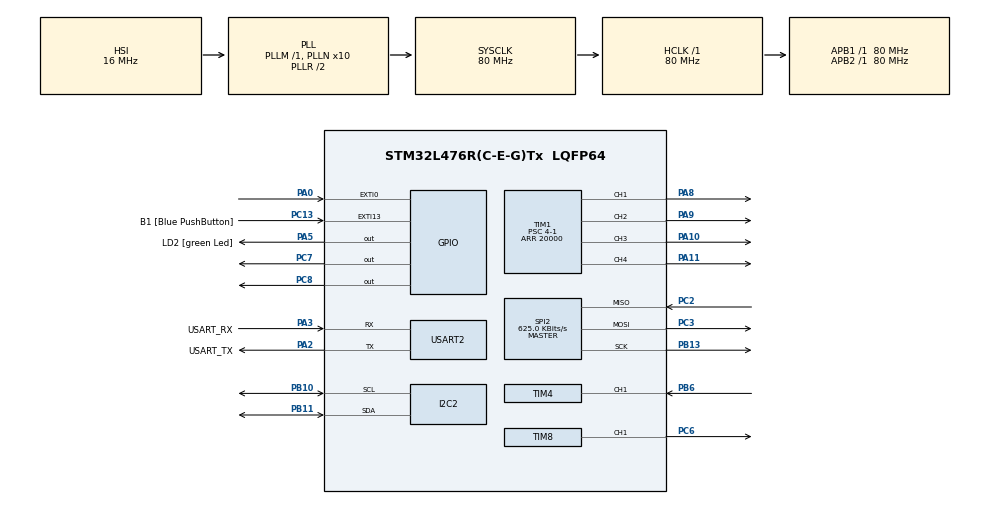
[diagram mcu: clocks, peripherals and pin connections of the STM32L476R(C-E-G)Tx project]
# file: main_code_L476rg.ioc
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I2C2.Timing=0x10D19CE4
Mcu.Family=STM32L4
Mcu.Name=STM32L476R(C-E-G)Tx
Mcu.Package=LQFP64
NVIC.EXTI0_IRQn=true\:0\:0\:false\:false\:true\:true\:true\:true
NVIC.PriorityGroup=NVIC_PRIORITYGROUP_4
NVIC.TIM2_IRQn=true\:0\:0\:false\:false\:true\:true\:true\:true
NVIC.TIM3_IRQn=true\:0\:0\:false\:false\:true\:true\:true\:true
NVIC.TIM4_IRQn=true\:0\:0\:false\:false\:true\:true\:true\:true
NVIC.USART2_IRQn=true\:0\:0\:false\:false\:true\:true\:true\:true
PA0.GPIO_ModeDefaultEXTI=GPIO_MODE_IT_FALLING
PA0.Signal=GPXTI0
PA10.Signal=S_TIM1_CH3
PA11.Signal=S_TIM1_CH4
PA13\ (JTMS-SWDIO).GPIO_Label=TMS
PA13\ (JTMS-SWDIO).Mode=Serial_Wire
PA13\ (JTMS-SWDIO).Signal=SYS_JTMS-SWDIO
PA14\ (JTCK-SWCLK).GPIO_Label=TCK
PA14\ (JTCK-SWCLK).Mode=Serial_Wire
PA14\ (JTCK-SWCLK).Signal=SYS_JTCK-SWCLK
PA2.GPIO_Label=USART_TX
PA2.GPIO_Mode=GPIO_MODE_AF_PP
PA2.GPIO_PuPd=GPIO_NOPULL
PA2.GPIO_Speed=GPIO_SPEED_FREQ_VERY_HIGH
PA2.Mode=Asynchronous
PA2.Signal=USART2_TX
PA3.GPIO_Label=USART_RX
PA3.GPIO_Mode=GPIO_MODE_AF_PP
PA3.GPIO_PuPd=GPIO_NOPULL
PA3.GPIO_Speed=GPIO_SPEED_FREQ_VERY_HIGH
PA3.Mode=Asynchronous
PA3.Signal=USART2_RX
PA5.GPIO_Label=LD2 [green Led]
PA5.GPIO_ModeDefaultOutputPP=GPIO_MODE_OUTPUT_PP
PA5.GPIO_PuPd=GPIO_NOPULL
PA5.GPIO_Speed=GPIO_SPEED_FREQ_LOW
PA5.Signal=GPIO_Output
PA8.Signal=S_TIM1_CH1
PA9.Signal=S_TIM1_CH2
PB10.Mode=I2C
PB10.Signal=I2C2_SCL
PB11.Mode=I2C
PB11.Signal=I2C2_SDA
PB13.Mode=Full_Duplex_Master
PB13.Signal=SPI2_SCK
PB3\ (JTDO-TRACESWO).GPIO_Label=SWO
PB3\ (JTDO-TRACESWO).Signal=SYS_JTDO-SWO
PB6.Signal=S_TIM4_CH1
PC13.GPIO_Label=B1 [Blue PushButton]
PC13.GPIO_ModeDefaultEXTI=GPIO_MODE_IT_FALLING
PC13.GPIO_PuPd=GPIO_NOPULL
PC13.Signal=GPXTI13
PC14-OSC32_IN\ (PC14).Mode=LSE-External-Oscillator
PC14-OSC32_IN\ (PC14).Signal=RCC_OSC32_IN
PC15-OSC32_OUT\ (PC15).Mode=LSE-External-Oscillator
PC15-OSC32_OUT\ (PC15).Signal=RCC_OSC32_OUT
PC2.Mode=Full_Duplex_Master
PC2.Signal=SPI2_MISO
PC3.Mode=Full_Duplex_Master
PC3.Signal=SPI2_MOSI
PC6.Signal=S_TIM8_CH1
PC7.PinState=GPIO_PIN_SET
PC7.Signal=GPIO_Output
PC8.Signal=GPIO_Output
PH0-OSC_IN\ (PH0).Signal=RCC_OSC_IN
PH1-OSC_OUT\ (PH1).Signal=RCC_OSC_OUT
ProjectManager.HeapSize=0x200
ProjectManager.StackSize=0x400
ProjectManager.TargetToolchain=STM32CubeIDE
RCC.ADCFreq_Value=64000000
RCC.AHBFreq_Value=80000000
RCC.APB1Freq_Value=80000000
RCC.APB1TimFreq_Value=80000000
RCC.APB2Freq_Value=80000000
RCC.APB2TimFreq_Value=80000000
RCC.CortexFreq_Value=80000000
RCC.HCLKFreq_Value=80000000
RCC.HSE_VALUE=8000000
RCC.HSI_VALUE=16000000
RCC.MSI_VALUE=4000000
RCC.PLLN=10
RCC.PLLSourceVirtual=RCC_PLLSOURCE_HSI
RCC.PREFETCH_ENABLE=1
RCC.SYSCLKFreq_VALUE=80000000
RCC.SYSCLKSource=RCC_SYSCLKSOURCE_PLLCLK
RCC.USBFreq_Value=64000000
RCC.VCOOutputFreq_Value=160000000
SH.S_TIM1_CH1.0=TIM1_CH1,PWM Generation1 CH1
SH.S_TIM1_CH2.0=TIM1_CH2,PWM Generation2 CH2
SH.S_TIM1_CH3.0=TIM1_CH3,PWM Generation3 CH3
SH.S_TIM1_CH4.0=TIM1_CH4,PWM Generation4 CH4
SH.S_TIM4_CH1.0=TIM4_CH1,Input_Capture1_from_TI1
SH.S_TIM8_CH1.0=TIM8_CH1,PWM Generation1 CH1
SPI2.BaudRatePrescaler=SPI_BAUDRATEPRESCALER_128
SPI2.CalculateBaudRate=625.0 KBits/s
SPI2.DataSize=SPI_DATASIZE_8BIT
SPI2.Direction=SPI_DIRECTION_2LINES
SPI2.Mode=SPI_MODE_MASTER
SPI2.VirtualType=VM_MASTER
TIM1.Channel-PWM\ Generation1\ CH1=TIM_CHANNEL_1
TIM1.Channel-PWM\ Generation2\ CH2=TIM_CHANNEL_2
TIM1.Channel-PWM\ Generation3\ CH3=TIM_CHANNEL_3
TIM1.Channel-PWM\ Generation4\ CH4=TIM_CHANNEL_4
TIM1.Period=20000
TIM1.Prescaler=4-1
TIM2.Period=200
TIM2.Prescaler=8000-1
TIM4.Channel-Input_Capture1_from_TI1=TIM_CHANNEL_1
TIM4.ICPolarity_CH1=TIM_INPUTCHANNELPOLARITY_BOTHEDGE
TIM4.Prescaler=80-1
TIM5.Prescaler=80-1
TIM8.Channel-PWM\ Generation1\ CH1=TIM_CHANNEL_1
TIM8.Period=65535
TIM8.Prescaler=80-1
TIM8.Pulse-PWM\ Generation1\ CH1=250
USART2.VirtualMode-Asynchronous=VM_ASYNC
VP_TIM1_VS_ClockSourceINT.Mode=Internal
VP_TIM2_VS_ClockSourceINT.Mode=Internal
VP_TIM3_VS_ClockSourceINT.Mode=Internal
VP_TIM4_VS_ClockSourceINT.Mode=Internal
VP_TIM5_VS_ClockSourceINT.Mode=Internal
VP_TIM8_VS_ClockSourceINT.Mode=Internal
board=NUCLEO-L476RG

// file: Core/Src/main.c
/* USER CODE BEGIN Header */
/**
  ******************************************************************************
  * @file           : main.c
  * @brief          : Main program body
  ******************************************************************************
  * @attention
  *
  * Copyright (c) 2025 STMicroelectronics.
  * All rights reserved.
  *
  * This software is licensed under terms that can be found in the LICENSE file
  * in the root directory of this software component.
  * If no LICENSE file comes with this software, it is provided AS-IS.
  *
  ******************************************************************************
  */
/* USER CODE END Header */
#include "main.h"

/* USER CODE BEGIN Includes */
#include "mainloop.h"
#include "nrf24l01p.h"
/* USER CODE END Includes */

I2C_HandleTypeDef hi2c2;

SPI_HandleTypeDef hspi2;

TIM_HandleTypeDef htim1;
TIM_HandleTypeDef htim2;
TIM_HandleTypeDef htim3;
TIM_HandleTypeDef htim4;
TIM_HandleTypeDef htim5;
TIM_HandleTypeDef htim8;

UART_HandleTypeDef huart2;

/* USER CODE BEGIN PV */
uint8_t rx_data[NRF24L01P_PAYLOAD_LENGTH] = {0};
uint8_t receivedString[NRF24L01P_PAYLOAD_LENGTH] = {0};
int flag = 0;
/* USER CODE END PV */

void SystemClock_Config(void);
static void MX_GPIO_Init(void);
static void MX_USART2_UART_Init(void);
static void MX_TIM1_Init(void);
static void MX_TIM2_Init(void);
static void MX_TIM3_Init(void);
static void MX_TIM4_Init(void);
static void MX_TIM5_Init(void);
static void MX_I2C2_Init(void);
static void MX_TIM8_Init(void);
static void MX_SPI2_Init(void);

/* USER CODE BEGIN 0 */

void HAL_GPIO_EXTI_Callback(uint16_t GPIO_Pin) {

	if(GPIO_Pin == NRF24L01P_IRQ_PIN_NUMBER) {
		HAL_GPIO_TogglePin(GPIOA, GPIO_PIN_5);
	    nrf24l01p_rx_receive(rx_data);
	    command_handler(rx_data);
	    flag = 1;
	}

}

/* USER CODE END 0 */

int main(void)
{

  /* MCU Configuration--------------------------------------------------------*/

  /* Reset of all peripherals, Initializes the Flash interface and the Systick. */
  HAL_Init();

  /* Configure the system clock */
  SystemClock_Config();

  /* Initialize all configured peripherals */
  MX_GPIO_Init();
  MX_USART2_UART_Init();
  MX_TIM1_Init();
  MX_TIM2_Init();
  MX_TIM3_Init();
  MX_TIM4_Init();
  MX_TIM5_Init();
  MX_I2C2_Init();
  MX_TIM8_Init();
  MX_SPI2_Init();
  /* USER CODE BEGIN 2 */
//  nrf24l01p_rx_init(2500, _250kbps);
  run();
  /* USER CODE END 2 */

  /* Infinite loop */
  while (1)
  {

  }
}

void SystemClock_Config(void)
{
  RCC_OscInitTypeDef RCC_OscInitStruct = {0};
  RCC_ClkInitTypeDef RCC_ClkInitStruct = {0};

  /** Configure the main internal regulator output voltage
  */
  if (HAL_PWREx_ControlVoltageScaling(PWR_REGULATOR_VOLTAGE_SCALE1) != HAL_OK)
  {
    Error_Handler();
  }

  /** Initializes the RCC Oscillators according to the specified parameters
  * in the RCC_OscInitTypeDef structure.
  */
  RCC_OscInitStruct.OscillatorType = RCC_OSCILLATORTYPE_HSI;
  RCC_OscInitStruct.HSIState = RCC_HSI_ON;
  RCC_OscInitStruct.HSICalibrationValue = RCC_HSICALIBRATION_DEFAULT;
  RCC_OscInitStruct.PLL.PLLState = RCC_PLL_ON;
  RCC_OscInitStruct.PLL.PLLSource = RCC_PLLSOURCE_HSI;
  RCC_OscInitStruct.PLL.PLLM = 1;
  RCC_OscInitStruct.PLL.PLLN = 10;
  RCC_OscInitStruct.PLL.PLLP = RCC_PLLP_DIV7;
  RCC_OscInitStruct.PLL.PLLQ = RCC_PLLQ_DIV2;
  RCC_OscInitStruct.PLL.PLLR = RCC_PLLR_DIV2;
  if (HAL_RCC_OscConfig(&RCC_OscInitStruct) != HAL_OK)
  {
    Error_Handler();
  }

  /** Initializes the CPU, AHB and APB buses clocks
  */
  RCC_ClkInitStruct.ClockType = RCC_CLOCKTYPE_HCLK|RCC_CLOCKTYPE_SYSCLK
                              |RCC_CLOCKTYPE_PCLK1|RCC_CLOCKTYPE_PCLK2;
  RCC_ClkInitStruct.SYSCLKSource = RCC_SYSCLKSOURCE_PLLCLK;
  RCC_ClkInitStruct.AHBCLKDivider = RCC_SYSCLK_DIV1;
  RCC_ClkInitStruct.APB1CLKDivider = RCC_HCLK_DIV1;
  RCC_ClkInitStruct.APB2CLKDivider = RCC_HCLK_DIV1;

  if (HAL_RCC_ClockConfig(&RCC_ClkInitStruct, FLASH_LATENCY_4) != HAL_OK)
  {
    Error_Handler();
  }
}

static void MX_I2C2_Init(void)
{

  hi2c2.Instance = I2C2;
  hi2c2.Init.Timing = 0x10D19CE4;
  hi2c2.Init.OwnAddress1 = 0;
  hi2c2.Init.AddressingMode = I2C_ADDRESSINGMODE_7BIT;
  hi2c2.Init.DualAddressMode = I2C_DUALADDRESS_DISABLE;
  hi2c2.Init.OwnAddress2 = 0;
  hi2c2.Init.OwnAddress2Masks = I2C_OA2_NOMASK;
  hi2c2.Init.GeneralCallMode = I2C_GENERALCALL_DISABLE;
  hi2c2.Init.NoStretchMode = I2C_NOSTRETCH_DISABLE;
  if (HAL_I2C_Init(&hi2c2) != HAL_OK)
  {
    Error_Handler();
  }

  /** Configure Analogue filter
  */
  if (HAL_I2CEx_ConfigAnalogFilter(&hi2c2, I2C_ANALOGFILTER_ENABLE) != HAL_OK)
  {
    Error_Handler();
  }

  /** Configure Digital filter
  */
  if (HAL_I2CEx_ConfigDigitalFilter(&hi2c2, 0) != HAL_OK)
  {
    Error_Handler();
  }

}

static void MX_SPI2_Init(void)
{

  /* SPI2 parameter configuration*/
  hspi2.Instance = SPI2;
  hspi2.Init.Mode = SPI_MODE_MASTER;
  hspi2.Init.Direction = SPI_DIRECTION_2LINES;
  hspi2.Init.DataSize = SPI_DATASIZE_8BIT;
  hspi2.Init.CLKPolarity = SPI_POLARITY_LOW;
  hspi2.Init.CLKPhase = SPI_PHASE_1EDGE;
  hspi2.Init.NSS = SPI_NSS_SOFT;
  hspi2.Init.BaudRatePrescaler = SPI_BAUDRATEPRESCALER_128;
  hspi2.Init.FirstBit = SPI_FIRSTBIT_MSB;
  hspi2.Init.TIMode = SPI_TIMODE_DISABLE;
  hspi2.Init.CRCCalculation = SPI_CRCCALCULATION_DISABLE;
  hspi2.Init.CRCPolynomial = 7;
  hspi2.Init.CRCLength = SPI_CRC_LENGTH_DATASIZE;
  hspi2.Init.NSSPMode = SPI_NSS_PULSE_ENABLE;
  if (HAL_SPI_Init(&hspi2) != HAL_OK)
  {
    Error_Handler();
  }

}

static void MX_TIM1_Init(void)
{

  TIM_ClockConfigTypeDef sClockSourceConfig = {0};
  TIM_MasterConfigTypeDef sMasterConfig = {0};
  TIM_OC_InitTypeDef sConfigOC = {0};
  TIM_BreakDeadTimeConfigTypeDef sBreakDeadTimeConfig = {0};

  htim1.Instance = TIM1;
  htim1.Init.Prescaler = 4-1;
  htim1.Init.CounterMode = TIM_COUNTERMODE_UP;
  htim1.Init.Period = 20000;
  htim1.Init.ClockDivision = TIM_CLOCKDIVISION_DIV1;
  htim1.Init.RepetitionCounter = 0;
  htim1.Init.AutoReloadPreload = TIM_AUTORELOAD_PRELOAD_DISABLE;
  if (HAL_TIM_Base_Init(&htim1) != HAL_OK)
  {
    Error_Handler();
  }
  sClockSourceConfig.ClockSource = TIM_CLOCKSOURCE_INTERNAL;
  if (HAL_TIM_ConfigClockSource(&htim1, &sClockSourceConfig) != HAL_OK)
  {
    Error_Handler();
  }
  if (HAL_TIM_PWM_Init(&htim1) != HAL_OK)
  {
    Error_Handler();
  }
  sMasterConfig.MasterOutputTrigger = TIM_TRGO_RESET;
  sMasterConfig.MasterOutputTrigger2 = TIM_TRGO2_RESET;
  sMasterConfig.MasterSlaveMode = TIM_MASTERSLAVEMODE_DISABLE;
  if (HAL_TIMEx_MasterConfigSynchronization(&htim1, &sMasterConfig) != HAL_OK)
  {
    Error_Handler();
  }
  sConfigOC.OCMode = TIM_OCMODE_PWM1;
  sConfigOC.Pulse = 0;
  sConfigOC.OCPolarity = TIM_OCPOLARITY_HIGH;
  sConfigOC.OCNPolarity = TIM_OCNPOLARITY_HIGH;
  sConfigOC.OCFastMode = TIM_OCFAST_DISABLE;
  sConfigOC.OCIdleState = TIM_OCIDLESTATE_RESET;
  sConfigOC.OCNIdleState = TIM_OCNIDLESTATE_RESET;
  if (HAL_TIM_PWM_ConfigChannel(&htim1, &sConfigOC, TIM_CHANNEL_1) != HAL_OK)
  {
    Error_Handler();
  }
  if (HAL_TIM_PWM_ConfigChannel(&htim1, &sConfigOC, TIM_CHANNEL_2) != HAL_OK)
  {
    Error_Handler();
  }
  if (HAL_TIM_PWM_ConfigChannel(&htim1, &sConfigOC, TIM_CHANNEL_3) != HAL_OK)
  {
    Error_Handler();
  }
  if (HAL_TIM_PWM_ConfigChannel(&htim1, &sConfigOC, TIM_CHANNEL_4) != HAL_OK)
  {
    Error_Handler();
  }
  sBreakDeadTimeConfig.OffStateRunMode = TIM_OSSR_DISABLE;
  sBreakDeadTimeConfig.OffStateIDLEMode = TIM_OSSI_DISABLE;
  sBreakDeadTimeConfig.LockLevel = TIM_LOCKLEVEL_OFF;
  sBreakDeadTimeConfig.DeadTime = 0;
  sBreakDeadTimeConfig.BreakState = TIM_BREAK_DISABLE;
  sBreakDeadTimeConfig.BreakPolarity = TIM_BREAKPOLARITY_HIGH;
  sBreakDeadTimeConfig.BreakFilter = 0;
  sBreakDeadTimeConfig.Break2State = TIM_BREAK2_DISABLE;
  sBreakDeadTimeConfig.Break2Polarity = TIM_BREAK2POLARITY_HIGH;
  sBreakDeadTimeConfig.Break2Filter = 0;
  sBreakDeadTimeConfig.AutomaticOutput = TIM_AUTOMATICOUTPUT_DISABLE;
  if (HAL_TIMEx_ConfigBreakDeadTime(&htim1, &sBreakDeadTimeConfig) != HAL_OK)
  {
    Error_Handler();
  }
  HAL_TIM_MspPostInit(&htim1);

}

static void MX_TIM2_Init(void)
{

  TIM_ClockConfigTypeDef sClockSourceConfig = {0};
  TIM_MasterConfigTypeDef sMasterConfig = {0};

  htim2.Instance = TIM2;
  htim2.Init.Prescaler = 8000-1;
  htim2.Init.CounterMode = TIM_COUNTERMODE_UP;
  htim2.Init.Period = 200;
  htim2.Init.ClockDivision = TIM_CLOCKDIVISION_DIV1;
  htim2.Init.AutoReloadPreload = TIM_AUTORELOAD_PRELOAD_DISABLE;
  if (HAL_TIM_Base_Init(&htim2) != HAL_OK)
  {
    Error_Handler();
  }
  sClockSourceConfig.ClockSource = TIM_CLOCKSOURCE_INTERNAL;
  if (HAL_TIM_ConfigClockSource(&htim2, &sClockSourceConfig) != HAL_OK)
  {
    Error_Handler();
  }
  sMasterConfig.MasterOutputTrigger = TIM_TRGO_RESET;
  sMasterConfig.MasterSlaveMode = TIM_MASTERSLAVEMODE_DISABLE;
  if (HAL_TIMEx_MasterConfigSynchronization(&htim2, &sMasterConfig) != HAL_OK)
  {
    Error_Handler();
  }

}

static void MX_TIM3_Init(void)
{

  TIM_ClockConfigTypeDef sClockSourceConfig = {0};
  TIM_MasterConfigTypeDef sMasterConfig = {0};

  htim3.Instance = TIM3;
  htim3.Init.Prescaler = 0;
  htim3.Init.CounterMode = TIM_COUNTERMODE_UP;
  htim3.Init.Period = 65535;
  htim3.Init.ClockDivision = TIM_CLOCKDIVISION_DIV1;
  htim3.Init.AutoReloadPreload = TIM_AUTORELOAD_PRELOAD_DISABLE;
  if (HAL_TIM_Base_Init(&htim3) != HAL_OK)
  {
    Error_Handler();
  }
  sClockSourceConfig.ClockSource = TIM_CLOCKSOURCE_INTERNAL;
  if (HAL_TIM_ConfigClockSource(&htim3, &sClockSourceConfig) != HAL_OK)
  {
    Error_Handler();
  }
  sMasterConfig.MasterOutputTrigger = TIM_TRGO_RESET;
  sMasterConfig.MasterSlaveMode = TIM_MASTERSLAVEMODE_DISABLE;
  if (HAL_TIMEx_MasterConfigSynchronization(&htim3, &sMasterConfig) != HAL_OK)
  {
    Error_Handler();
  }

}

static void MX_TIM4_Init(void)
{

  TIM_ClockConfigTypeDef sClockSourceConfig = {0};
  TIM_MasterConfigTypeDef sMasterConfig = {0};
  TIM_IC_InitTypeDef sConfigIC = {0};

  htim4.Instance = TIM4;
  htim4.Init.Prescaler = 80-1;
  htim4.Init.CounterMode = TIM_COUNTERMODE_UP;
  htim4.Init.Period = 65535;
  htim4.Init.ClockDivision = TIM_CLOCKDIVISION_DIV1;
  htim4.Init.AutoReloadPreload = TIM_AUTORELOAD_PRELOAD_DISABLE;
  if (HAL_TIM_Base_Init(&htim4) != HAL_OK)
  {
    Error_Handler();
  }
  sClockSourceConfig.ClockSource = TIM_CLOCKSOURCE_INTERNAL;
  if (HAL_TIM_ConfigClockSource(&htim4, &sClockSourceConfig) != HAL_OK)
  {
    Error_Handler();
  }
  if (HAL_TIM_IC_Init(&htim4) != HAL_OK)
  {
    Error_Handler();
  }
  sMasterConfig.MasterOutputTrigger = TIM_TRGO_RESET;
  sMasterConfig.MasterSlaveMode = TIM_MASTERSLAVEMODE_DISABLE;
  if (HAL_TIMEx_MasterConfigSynchronization(&htim4, &sMasterConfig) != HAL_OK)
  {
    Error_Handler();
  }
  sConfigIC.ICPolarity = TIM_INPUTCHANNELPOLARITY_BOTHEDGE;
  sConfigIC.ICSelection = TIM_ICSELECTION_DIRECTTI;
  sConfigIC.ICPrescaler = TIM_ICPSC_DIV1;
  sConfigIC.ICFilter = 0;
  if (HAL_TIM_IC_ConfigChannel(&htim4, &sConfigIC, TIM_CHANNEL_1) != HAL_OK)
  {
    Error_Handler();
  }

}

static void MX_TIM5_Init(void)
{

  TIM_ClockConfigTypeDef sClockSourceConfig = {0};
  TIM_MasterConfigTypeDef sMasterConfig = {0};

  htim5.Instance = TIM5;
  htim5.Init.Prescaler = 80-1;
  htim5.Init.CounterMode = TIM_COUNTERMODE_UP;
  htim5.Init.Period = 4294967295;
  htim5.Init.ClockDivision = TIM_CLOCKDIVISION_DIV1;
  htim5.Init.AutoReloadPreload = TIM_AUTORELOAD_PRELOAD_DISABLE;
  if (HAL_TIM_Base_Init(&htim5) != HAL_OK)
  {
    Error_Handler();
  }
  sClockSourceConfig.ClockSource = TIM_CLOCKSOURCE_INTERNAL;
  if (HAL_TIM_ConfigClockSource(&htim5, &sClockSourceConfig) != HAL_OK)
  {
    Error_Handler();
  }
  sMasterConfig.MasterOutputTrigger = TIM_TRGO_RESET;
  sMasterConfig.MasterSlaveMode = TIM_MASTERSLAVEMODE_DISABLE;
  if (HAL_TIMEx_MasterConfigSynchronization(&htim5, &sMasterConfig) != HAL_OK)
  {
    Error_Handler();
  }

}

static void MX_TIM8_Init(void)
{

  TIM_ClockConfigTypeDef sClockSourceConfig = {0};
  TIM_MasterConfigTypeDef sMasterConfig = {0};
  TIM_OC_InitTypeDef sConfigOC = {0};
  TIM_BreakDeadTimeConfigTypeDef sBreakDeadTimeConfig = {0};

  htim8.Instance = TIM8;
  htim8.Init.Prescaler = 80-1;
  htim8.Init.CounterMode = TIM_COUNTERMODE_UP;
  htim8.Init.Period = 65535;
  htim8.Init.ClockDivision = TIM_CLOCKDIVISION_DIV1;
  htim8.Init.RepetitionCounter = 0;
  htim8.Init.AutoReloadPreload = TIM_AUTORELOAD_PRELOAD_DISABLE;
  if (HAL_TIM_Base_Init(&htim8) != HAL_OK)
  {
    Error_Handler();
  }
  sClockSourceConfig.ClockSource = TIM_CLOCKSOURCE_INTERNAL;
  if (HAL_TIM_ConfigClockSource(&htim8, &sClockSourceConfig) != HAL_OK)
  {
    Error_Handler();
  }
  if (HAL_TIM_PWM_Init(&htim8) != HAL_OK)
  {
    Error_Handler();
  }
  sMasterConfig.MasterOutputTrigger = TIM_TRGO_RESET;
  sMasterConfig.MasterOutputTrigger2 = TIM_TRGO2_RESET;
  sMasterConfig.MasterSlaveMode = TIM_MASTERSLAVEMODE_DISABLE;
  if (HAL_TIMEx_MasterConfigSynchronization(&htim8, &sMasterConfig) != HAL_OK)
  {
    Error_Handler();
  }
  sConfigOC.OCMode = TIM_OCMODE_PWM1;
  sConfigOC.Pulse = 250;
  sConfigOC.OCPolarity = TIM_OCPOLARITY_HIGH;
  sConfigOC.OCNPolarity = TIM_OCNPOLARITY_HIGH;
  sConfigOC.OCFastMode = TIM_OCFAST_DISABLE;
  sConfigOC.OCIdleState = TIM_OCIDLESTATE_RESET;
  sConfigOC.OCNIdleState = TIM_OCNIDLESTATE_RESET;
  if (HAL_TIM_PWM_ConfigChannel(&htim8, &sConfigOC, TIM_CHANNEL_1) != HAL_OK)
  {
    Error_Handler();
  }
  sBreakDeadTimeConfig.OffStateRunMode = TIM_OSSR_DISABLE;
  sBreakDeadTimeConfig.OffStateIDLEMode = TIM_OSSI_DISABLE;
  sBreakDeadTimeConfig.LockLevel = TIM_LOCKLEVEL_OFF;
  sBreakDeadTimeConfig.DeadTime = 0;
  sBreakDeadTimeConfig.BreakState = TIM_BREAK_DISABLE;
  sBreakDeadTimeConfig.BreakPolarity = TIM_BREAKPOLARITY_HIGH;
  sBreakDeadTimeConfig.BreakFilter = 0;
  sBreakDeadTimeConfig.Break2State = TIM_BREAK2_DISABLE;
  sBreakDeadTimeConfig.Break2Polarity = TIM_BREAK2POLARITY_HIGH;
  sBreakDeadTimeConfig.Break2Filter = 0;
  sBreakDeadTimeConfig.AutomaticOutput = TIM_AUTOMATICOUTPUT_DISABLE;
  if (HAL_TIMEx_ConfigBreakDeadTime(&htim8, &sBreakDeadTimeConfig) != HAL_OK)
  {
    Error_Handler();
  }
  HAL_TIM_MspPostInit(&htim8);

}

static void MX_USART2_UART_Init(void)
{

  huart2.Instance = USART2;
  huart2.Init.BaudRate = 115200;
  huart2.Init.WordLength = UART_WORDLENGTH_8B;
  huart2.Init.StopBits = UART_STOPBITS_1;
  huart2.Init.Parity = UART_PARITY_NONE;
  huart2.Init.Mode = UART_MODE_TX_RX;
  huart2.Init.HwFlowCtl = UART_HWCONTROL_NONE;
  huart2.Init.OverSampling = UART_OVERSAMPLING_16;
  huart2.Init.OneBitSampling = UART_ONE_BIT_SAMPLE_DISABLE;
  huart2.AdvancedInit.AdvFeatureInit = UART_ADVFEATURE_NO_INIT;
  if (HAL_UART_Init(&huart2) != HAL_OK)
  {
    Error_Handler();
  }

}

static void MX_GPIO_Init(void)
{
  GPIO_InitTypeDef GPIO_InitStruct = {0};

  /* GPIO Ports Clock Enable */
  __HAL_RCC_GPIOC_CLK_ENABLE();
  __HAL_RCC_GPIOH_CLK_ENABLE();
  __HAL_RCC_GPIOA_CLK_ENABLE();
  __HAL_RCC_GPIOB_CLK_ENABLE();

  /*Configure GPIO pin Output Level */
  HAL_GPIO_WritePin(LD2_GPIO_Port, LD2_Pin, GPIO_PIN_RESET);

  /*Configure GPIO pin Output Level */
  HAL_GPIO_WritePin(GPIOC, GPIO_PIN_7, GPIO_PIN_SET);

  /*Configure GPIO pin Output Level */
  HAL_GPIO_WritePin(GPIOC, GPIO_PIN_8, GPIO_PIN_RESET);

  /*Configure GPIO pin : B1_Pin */
  GPIO_InitStruct.Pin = B1_Pin;
  GPIO_InitStruct.Mode = GPIO_MODE_IT_FALLING;
  GPIO_InitStruct.Pull = GPIO_NOPULL;
  HAL_GPIO_Init(B1_GPIO_Port, &GPIO_InitStruct);

  /*Configure GPIO pin : PA0 */
  GPIO_InitStruct.Pin = GPIO_PIN_0;
  GPIO_InitStruct.Mode = GPIO_MODE_IT_FALLING;
  GPIO_InitStruct.Pull = GPIO_NOPULL;
  HAL_GPIO_Init(GPIOA, &GPIO_InitStruct);

  /*Configure GPIO pin : LD2_Pin */
  GPIO_InitStruct.Pin = LD2_Pin;
  GPIO_InitStruct.Mode = GPIO_MODE_OUTPUT_PP;
  GPIO_InitStruct.Pull = GPIO_NOPULL;
  GPIO_InitStruct.Speed = GPIO_SPEED_FREQ_LOW;
  HAL_GPIO_Init(LD2_GPIO_Port, &GPIO_InitStruct);

  /*Configure GPIO pins : PC7 PC8 */
  GPIO_InitStruct.Pin = GPIO_PIN_7|GPIO_PIN_8;
  GPIO_InitStruct.Mode = GPIO_MODE_OUTPUT_PP;
  GPIO_InitStruct.Pull = GPIO_NOPULL;
  GPIO_InitStruct.Speed = GPIO_SPEED_FREQ_LOW;
  HAL_GPIO_Init(GPIOC, &GPIO_InitStruct);

  /* EXTI interrupt init*/
  HAL_NVIC_SetPriority(EXTI0_IRQn, 0, 0);
  HAL_NVIC_EnableIRQ(EXTI0_IRQn);

}

void Error_Handler(void)
{
  __disable_irq();
  while (1)
  {
  }
}
